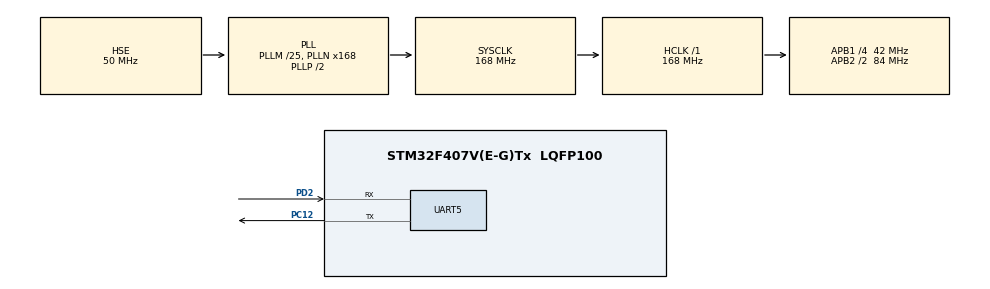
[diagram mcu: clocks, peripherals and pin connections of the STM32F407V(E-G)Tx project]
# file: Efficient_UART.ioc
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Dma.Request0=UART5_RX
Dma.UART5_RX.0.Direction=DMA_PERIPH_TO_MEMORY
Dma.UART5_RX.0.FIFOMode=DMA_FIFOMODE_DISABLE
Dma.UART5_RX.0.Instance=DMA1_Stream0
Dma.UART5_RX.0.MemDataAlignment=DMA_MDATAALIGN_BYTE
Dma.UART5_RX.0.MemInc=DMA_MINC_ENABLE
Dma.UART5_RX.0.Mode=DMA_CIRCULAR
Dma.UART5_RX.0.PeriphDataAlignment=DMA_PDATAALIGN_BYTE
Dma.UART5_RX.0.PeriphInc=DMA_PINC_DISABLE
Dma.UART5_RX.0.Priority=DMA_PRIORITY_LOW
FREERTOS.Tasks01=defaultTask,24,128,StartDefaultTask,Default,NULL,Dynamic,NULL,NULL
Mcu.Family=STM32F4
Mcu.Name=STM32F407V(E-G)Tx
Mcu.Package=LQFP100
NVIC.DMA1_Stream0_IRQn=true\:5\:0\:false\:false\:true\:true\:false\:true\:true
NVIC.PriorityGroup=NVIC_PRIORITYGROUP_4
NVIC.TIM4_IRQn=true\:15\:0\:false\:false\:true\:false\:false\:true\:true
NVIC.TimeBase=TIM4_IRQn
NVIC.TimeBaseIP=TIM4
NVIC.UART5_IRQn=true\:5\:0\:false\:false\:true\:true\:true\:true\:true
PA13.Mode=Serial_Wire
PA13.Signal=SYS_JTMS-SWDIO
PA14.Mode=Serial_Wire
PA14.Signal=SYS_JTCK-SWCLK
PC12.Mode=Asynchronous
PC12.Signal=UART5_TX
PD2.Mode=Asynchronous
PD2.Signal=UART5_RX
PH0-OSC_IN.Mode=HSE-External-Clock-Source
PH0-OSC_IN.Signal=RCC_OSC_IN
PH1-OSC_OUT.Mode=HSE-External-Clock-Source
PH1-OSC_OUT.Signal=RCC_OSC_OUT
ProjectManager.HeapSize=0x200
ProjectManager.StackSize=0x400
ProjectManager.TargetToolchain=MDK-ARM V5.32
RCC.48MHZClocksFreq_Value=84000000
RCC.AHBFreq_Value=168000000
RCC.APB1CLKDivider=RCC_HCLK_DIV4
RCC.APB1Freq_Value=42000000
RCC.APB1TimFreq_Value=84000000
RCC.APB2CLKDivider=RCC_HCLK_DIV2
RCC.APB2Freq_Value=84000000
RCC.APB2TimFreq_Value=168000000
RCC.CortexFreq_Value=168000000
RCC.HCLKFreq_Value=168000000
RCC.HSE_VALUE=50000000
RCC.HSI_VALUE=16000000
RCC.LSE_VALUE=32768
RCC.PLLM=25
RCC.PLLN=168
RCC.PLLSourceVirtual=RCC_PLLSOURCE_HSE
RCC.SYSCLKFreq_VALUE=168000000
RCC.SYSCLKSource=RCC_SYSCLKSOURCE_PLLCLK
RCC.VCOOutputFreq_Value=336000000
UART5.VirtualMode=Asynchronous
VP_FREERTOS_VS_CMSIS_V2.Mode=CMSIS_V2
VP_SYS_VS_tim4.Mode=TIM4
board=custom

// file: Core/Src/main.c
/* USER CODE BEGIN Header */
/**
  ******************************************************************************
  * @file           : main.c
  * @brief          : Main program body
  ******************************************************************************
  * @attention
  *
  * Copyright (c) 2025 STMicroelectronics.
  * All rights reserved.
  *
  * This software is licensed under terms that can be found in the LICENSE file
  * in the root directory of this software component.
  * If no LICENSE file comes with this software, it is provided AS-IS.
  *
  ******************************************************************************
  */
/* USER CODE END Header */
#include "main.h"
#include "cmsis_os.h"
#include "dma.h"
#include "usart.h"
#include "gpio.h"

void SystemClock_Config(void);
void MX_FREERTOS_Init(void);

int main(void)
{

  /* MCU Configuration--------------------------------------------------------*/

  /* Reset of all peripherals, Initializes the Flash interface and the Systick. */
  HAL_Init();

  /* Configure the system clock */
  SystemClock_Config();

  /* Initialize all configured peripherals */
  MX_GPIO_Init();
  MX_DMA_Init();
  MX_UART5_Init();

  /* Init scheduler */
  osKernelInitialize();

  /* Call init function for freertos objects (in freertos.c) */
  MX_FREERTOS_Init();

  /* Start scheduler */
  osKernelStart();

  /* We should never get here as control is now taken by the scheduler */
  /* Infinite loop */
  while (1)
  {

  }
}

void SystemClock_Config(void)
{
  RCC_OscInitTypeDef RCC_OscInitStruct = {0};
  RCC_ClkInitTypeDef RCC_ClkInitStruct = {0};

  /** Configure the main internal regulator output voltage
  */
  __HAL_RCC_PWR_CLK_ENABLE();
  __HAL_PWR_VOLTAGESCALING_CONFIG(PWR_REGULATOR_VOLTAGE_SCALE1);

  /** Initializes the RCC Oscillators according to the specified parameters
  * in the RCC_OscInitTypeDef structure.
  */
  RCC_OscInitStruct.OscillatorType = RCC_OSCILLATORTYPE_HSE;
  RCC_OscInitStruct.HSEState = RCC_HSE_BYPASS;
  RCC_OscInitStruct.PLL.PLLState = RCC_PLL_ON;
  RCC_OscInitStruct.PLL.PLLSource = RCC_PLLSOURCE_HSE;
  RCC_OscInitStruct.PLL.PLLM = 25;
  RCC_OscInitStruct.PLL.PLLN = 168;
  RCC_OscInitStruct.PLL.PLLP = RCC_PLLP_DIV2;
  RCC_OscInitStruct.PLL.PLLQ = 4;
  if (HAL_RCC_OscConfig(&RCC_OscInitStruct) != HAL_OK)
  {
    Error_Handler();
  }

  /** Initializes the CPU, AHB and APB buses clocks
  */
  RCC_ClkInitStruct.ClockType = RCC_CLOCKTYPE_HCLK|RCC_CLOCKTYPE_SYSCLK
                              |RCC_CLOCKTYPE_PCLK1|RCC_CLOCKTYPE_PCLK2;
  RCC_ClkInitStruct.SYSCLKSource = RCC_SYSCLKSOURCE_PLLCLK;
  RCC_ClkInitStruct.AHBCLKDivider = RCC_SYSCLK_DIV1;
  RCC_ClkInitStruct.APB1CLKDivider = RCC_HCLK_DIV4;
  RCC_ClkInitStruct.APB2CLKDivider = RCC_HCLK_DIV2;

  if (HAL_RCC_ClockConfig(&RCC_ClkInitStruct, FLASH_LATENCY_5) != HAL_OK)
  {
    Error_Handler();
  }
}

void HAL_TIM_PeriodElapsedCallback(TIM_HandleTypeDef *htim)
{
  if (htim->Instance == TIM4) {
    HAL_IncTick();
  }
}

void Error_Handler(void)
{
  __disable_irq();
  while (1)
  {
  }
}

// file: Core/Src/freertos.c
/* USER CODE BEGIN Header */
/**
  ******************************************************************************
  * File Name          : freertos.c
  * Description        : Code for freertos applications
  ******************************************************************************
  * @attention
  *
  * Copyright (c) 2025 STMicroelectronics.
  * All rights reserved.
  *
  * This software is licensed under terms that can be found in the LICENSE file
  * in the root directory of this software component.
  * If no LICENSE file comes with this software, it is provided AS-IS.
  *
  ******************************************************************************
  */
/* USER CODE END Header */

#include "FreeRTOS.h"
#include "task.h"
#include "main.h"
#include "cmsis_os.h"

/* USER CODE BEGIN Includes */
#include "semphr.h"
#include "queue.h"
#include "usart.h"
#include "FIFO.h"
/* USER CODE END Includes */

/* USER CODE BEGIN PTD */
extern FIFO_BUFFER_CTRL uart_fifo_buffer;
/* USER CODE END PTD */

/* Definitions for defaultTask */
osThreadId_t defaultTaskHandle;
const osThreadAttr_t defaultTask_attributes = {
  .name = "defaultTask",
  .stack_size = 128 * 4,
  .priority = (osPriority_t) osPriorityNormal,
};

/* USER CODE BEGIN FunctionPrototypes */
void uart_analysis_task(void *argument);

QueueHandle_t Uart_Analysis_Queue_Handle;
/* USER CODE END FunctionPrototypes */

void StartDefaultTask(void *argument);

void MX_FREERTOS_Init(void); /* (MISRA C 2004 rule 8.1) */

void MX_FREERTOS_Init(void) {

  /* USER CODE BEGIN RTOS_QUEUES */
  /* add queues, ... */
	Uart_Analysis_Queue_Handle = xQueueCreate(16, 4);
  /* USER CODE END RTOS_QUEUES */

  /* Create the thread(s) */
  /* creation of defaultTask */
  defaultTaskHandle = osThreadNew(StartDefaultTask, NULL, &defaultTask_attributes);

  /* USER CODE BEGIN RTOS_THREADS */
  /* add threads, ... */
	BaseType_t result;

	result = xTaskCreate(uart_analysis_task, "uart_analysis_task", 256, NULL, osPriorityNormal4, NULL);
	configASSERT(result == pdPASS);
  /* USER CODE END RTOS_THREADS */

}

void StartDefaultTask(void *argument)
{
  for(;;)
  {
    osDelay(1);
  }
}

/* USER CODE BEGIN Application */
uint8_t temp_data[100] = {0};// 临时数据缓冲区，用于存储从FIFO读取的数据
void uart_analysis_task(void *argument)
{
	// 使能UART5的空闲中断
	__HAL_UART_ENABLE_IT(&huart5, UART_IT_IDLE);

	// 启动DMA接收，数据直接存入FIFO缓冲区
	HAL_UART_Receive_DMA(&huart5, uart_fifo_buffer.circular_buffer, FIFO_MAX_BUFFER);

	// 中断标志变量，用于接收队列消息
	uint32_t isr_flag = 0;

	// 临时缓冲区索引
	uint8_t i = 0;
	for(;;)
  {
	    // 阻塞等待队列消息（来自中断）
		xQueueReceive(Uart_Analysis_Queue_Handle, &isr_flag, portMAX_DELAY);

		while(FIFO_Buffer_is_Empty(&uart_fifo_buffer) != 1){
			// 循环读取直到FIFO为空

			Get_Byte_from_FIFO_Buffer(&uart_fifo_buffer, &temp_data[i]);
			// 从FIFO获取一个字节到临时缓冲区
			i = (i+1)%100;
			//下面可以放数据分析的代码
		}
  }
}
/* USER CODE END Application */
